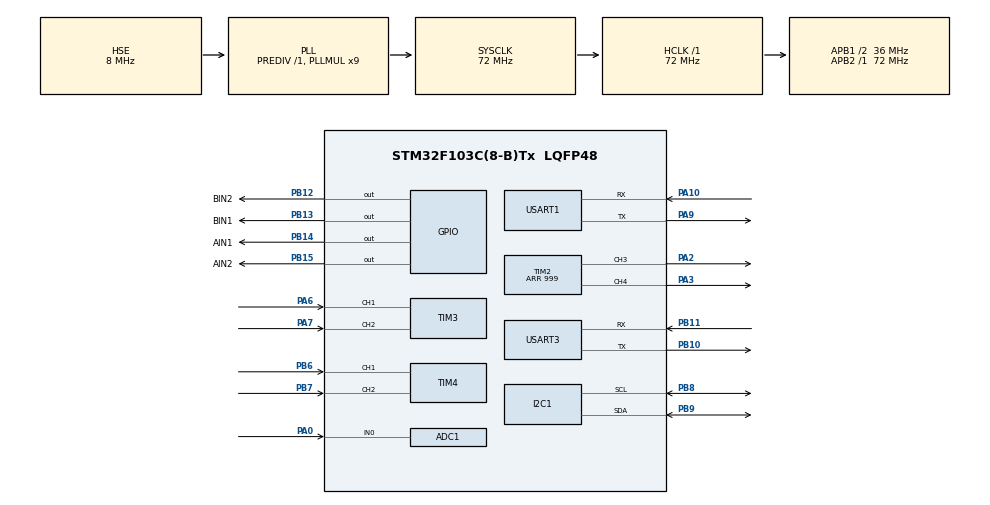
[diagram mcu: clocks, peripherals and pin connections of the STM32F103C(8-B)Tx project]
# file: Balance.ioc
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ADC1.Channel-0\#ChannelRegularConversion=ADC_CHANNEL_0
ADC1.NbrOfConversionFlag=1
ADC1.Rank-0\#ChannelRegularConversion=1
ADC1.SamplingTime-0\#ChannelRegularConversion=ADC_SAMPLETIME_1CYCLE_5
ADC1.master=1
I2C1.I2C_Mode=I2C_Fast
Mcu.Family=STM32F1
Mcu.Name=STM32F103C(8-B)Tx
Mcu.Package=LQFP48
NVIC.PriorityGroup=NVIC_PRIORITYGROUP_4
PA0-WKUP.Signal=ADCx_IN0
PA10.Mode=Asynchronous
PA10.Signal=USART1_RX
PA13.Mode=Serial_Wire
PA13.Signal=SYS_JTMS-SWDIO
PA14.Mode=Serial_Wire
PA14.Signal=SYS_JTCK-SWCLK
PA2.Signal=S_TIM2_CH3
PA3.Signal=S_TIM2_CH4
PA6.GPIO_PuPd=GPIO_PULLUP
PA6.Signal=S_TIM3_CH1
PA7.GPIO_PuPd=GPIO_PULLUP
PA7.Signal=S_TIM3_CH2
PA9.Mode=Asynchronous
PA9.Signal=USART1_TX
PB10.Mode=Asynchronous
PB10.Signal=USART3_TX
PB11.Mode=Asynchronous
PB11.Signal=USART3_RX
PB12.GPIO_Label=BIN2
PB12.GPIO_PuPd=GPIO_NOPULL
PB12.GPIO_Speed=GPIO_SPEED_FREQ_HIGH
PB12.Signal=GPIO_Output
PB13.GPIO_Label=BIN1
PB13.GPIO_PuPd=GPIO_NOPULL
PB13.GPIO_Speed=GPIO_SPEED_FREQ_HIGH
PB13.Signal=GPIO_Output
PB14.GPIO_Label=AIN1
PB14.GPIO_Speed=GPIO_SPEED_FREQ_HIGH
PB14.Signal=GPIO_Output
PB15.GPIO_Label=AIN2
PB15.GPIO_Speed=GPIO_SPEED_FREQ_HIGH
PB15.Signal=GPIO_Output
PB6.GPIO_PuPd=GPIO_PULLUP
PB6.Signal=S_TIM4_CH1
PB7.GPIO_PuPd=GPIO_PULLUP
PB7.Signal=S_TIM4_CH2
PB8.Mode=I2C
PB8.Signal=I2C1_SCL
PB9.Mode=I2C
PB9.Signal=I2C1_SDA
PD0-OSC_IN.Mode=HSE-External-Oscillator
PD0-OSC_IN.Signal=RCC_OSC_IN
PD1-OSC_OUT.Mode=HSE-External-Oscillator
PD1-OSC_OUT.Signal=RCC_OSC_OUT
ProjectManager.HeapSize=0x200
ProjectManager.StackSize=0x400
ProjectManager.TargetToolchain=SW4STM32
RCC.ADCPresc=RCC_ADCPCLK2_DIV6
RCC.AHBFreq_Value=72000000
RCC.APB1CLKDivider=RCC_HCLK_DIV2
RCC.APB1Freq_Value=36000000
RCC.APB1TimFreq_Value=72000000
RCC.APB2Freq_Value=72000000
RCC.APB2TimFreq_Value=72000000
RCC.HCLKFreq_Value=72000000
RCC.PLLMUL=RCC_PLL_MUL9
RCC.PLLSourceVirtual=RCC_PLLSOURCE_HSE
RCC.SYSCLKFreq_VALUE=72000000
RCC.SYSCLKSource=RCC_SYSCLKSOURCE_PLLCLK
RCC.USBFreq_Value=72000000
SH.ADCx_IN0.0=ADC1_IN0,IN0
SH.S_TIM2_CH3.0=TIM2_CH3,PWM Generation3 CH3
SH.S_TIM2_CH4.0=TIM2_CH4,PWM Generation4 CH4
SH.S_TIM3_CH1.0=TIM3_CH1,Encoder_Interface
SH.S_TIM3_CH2.0=TIM3_CH2,Encoder_Interface
SH.S_TIM4_CH1.0=TIM4_CH1,Encoder_Interface
SH.S_TIM4_CH2.0=TIM4_CH2,Encoder_Interface
TIM2.Channel-PWM\ Generation3\ CH3=TIM_CHANNEL_3
TIM2.Channel-PWM\ Generation4\ CH4=TIM_CHANNEL_4
TIM2.Period=999
USART1.VirtualMode=VM_ASYNC
USART3.VirtualMode=VM_ASYNC
board=custom

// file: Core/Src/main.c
/* USER CODE BEGIN Header */
/**
  ******************************************************************************
  * @file           : main.c
  * @brief          : Main program body
  ******************************************************************************
  * @attention
  *
  * Copyright (c) 2022 STMicroelectronics.
  * All rights reserved.
  *
  * This software is licensed under terms that can be found in the LICENSE file
  * in the root directory of this software component.
  * If no LICENSE file comes with this software, it is provided AS-IS.
  *
  ******************************************************************************
  */
/* USER CODE END Header */
#include "main.h"
#include "adc.h"
#include "i2c.h"
#include "tim.h"
#include "usart.h"
#include "gpio.h"

/* USER CODE BEGIN Includes */
#include "../../Bsp/MPU6050/mpu6050.h"
/* USER CODE END Includes */

/* USER CODE BEGIN PTD */
extern UART_HandleTypeDef huart1;
extern I2C_HandleTypeDef hi2c1;
/* USER CODE END PTD */

void SystemClock_Config(void);

int main(void)
{

  /* MCU Configuration--------------------------------------------------------*/

  /* Reset of all peripherals, Initializes the Flash interface and the Systick. */
  HAL_Init();

  /* USER CODE BEGIN Init */
    RetargetInit(&huart1);
  /* USER CODE END Init */

  /* Configure the system clock */
  SystemClock_Config();

  /* Initialize all configured peripherals */
  MX_GPIO_Init();
  MX_ADC1_Init();
  MX_I2C1_Init();
  MX_TIM2_Init();
  MX_TIM3_Init();
  MX_TIM4_Init();
  MX_USART1_UART_Init();
  MX_USART3_UART_Init();
  /* USER CODE BEGIN 2 */
    MPU6050_initialize();
    DMP_Init();
    printf("aaa");
    HAL_TIM_Encoder_Start(&htim3,TIM_CHANNEL_1 | TIM_CHANNEL_2);
    HAL_TIM_Encoder_Start(&htim4,TIM_CHANNEL_1 | TIM_CHANNEL_2);
    HAL_TIM_PWM_Start(&htim2,TIM_CHANNEL_3);
    HAL_TIM_PWM_Start(&htim2,TIM_CHANNEL_4);
//    HAL_GPIO_WritePin(GPIOB,BIN1_Pin,GPIO_PIN_RESET);
//    HAL_GPIO_WritePin(GPIOB,BIN2_Pin,GPIO_PIN_RESET);
//    HAL_GPIO_WritePin(GPIOB,AIN1_Pin,GPIO_PIN_RESET);
//    HAL_GPIO_WritePin(GPIOB,AIN2_Pin,GPIO_PIN_RESET);

    Main();
  /* USER CODE END 2 */

  /* Infinite loop */
  while (1)
  {
//    int pwmVal=0;
//    /* USER CODE BEGIN 3 */
//      int 	Direction = __HAL_TIM_IS_TIM_COUNTING_DOWN(&htim4);   //读取电机转动方向
//      int CaptureNumber =	(short)__HAL_TIM_GET_COUNTER(&htim4);	  //读取编码器数�?
//      __HAL_TIM_GET_COUNTER(&htim4) = 0;							  //计数器�?�重新置�?
//      printf("Direction is %d \r\n",Direction);
//      HAL_Delay(10);
//      printf("CaptureNumber is %d \r\n",CaptureNumber);
//      HAL_Delay(500);
        Read_DMP();
      //printf("%f\r\n",gyro[0]);

//      while (pwmVal< 500) {
//          pwmVal++;
//                  __HAL_TIM_SetCompare(&htim2, TIM_CHANNEL_1, pwmVal);    //修改比较值，修改占空比
////		  TIM3->CCR1 = pwmVal;    与上方相同
//          HAL_Delay(1);
//      }
  }
  /* USER CODE END 3 */
}

void SystemClock_Config(void)
{
  RCC_OscInitTypeDef RCC_OscInitStruct = {0};
  RCC_ClkInitTypeDef RCC_ClkInitStruct = {0};
  RCC_PeriphCLKInitTypeDef PeriphClkInit = {0};

  /** Initializes the RCC Oscillators according to the specified parameters
  * in the RCC_OscInitTypeDef structure.
  */
  RCC_OscInitStruct.OscillatorType = RCC_OSCILLATORTYPE_HSE;
  RCC_OscInitStruct.HSEState = RCC_HSE_ON;
  RCC_OscInitStruct.HSEPredivValue = RCC_HSE_PREDIV_DIV1;
  RCC_OscInitStruct.HSIState = RCC_HSI_ON;
  RCC_OscInitStruct.PLL.PLLState = RCC_PLL_ON;
  RCC_OscInitStruct.PLL.PLLSource = RCC_PLLSOURCE_HSE;
  RCC_OscInitStruct.PLL.PLLMUL = RCC_PLL_MUL9;
  if (HAL_RCC_OscConfig(&RCC_OscInitStruct) != HAL_OK)
  {
    Error_Handler();
  }

  /** Initializes the CPU, AHB and APB buses clocks
  */
  RCC_ClkInitStruct.ClockType = RCC_CLOCKTYPE_HCLK|RCC_CLOCKTYPE_SYSCLK
                              |RCC_CLOCKTYPE_PCLK1|RCC_CLOCKTYPE_PCLK2;
  RCC_ClkInitStruct.SYSCLKSource = RCC_SYSCLKSOURCE_PLLCLK;
  RCC_ClkInitStruct.AHBCLKDivider = RCC_SYSCLK_DIV1;
  RCC_ClkInitStruct.APB1CLKDivider = RCC_HCLK_DIV2;
  RCC_ClkInitStruct.APB2CLKDivider = RCC_HCLK_DIV1;

  if (HAL_RCC_ClockConfig(&RCC_ClkInitStruct, FLASH_LATENCY_2) != HAL_OK)
  {
    Error_Handler();
  }
  PeriphClkInit.PeriphClockSelection = RCC_PERIPHCLK_ADC;
  PeriphClkInit.AdcClockSelection = RCC_ADCPCLK2_DIV6;
  if (HAL_RCCEx_PeriphCLKConfig(&PeriphClkInit) != HAL_OK)
  {
    Error_Handler();
  }
}

void Error_Handler(void)
{
  __disable_irq();
  while (1)
  {
  }
}
